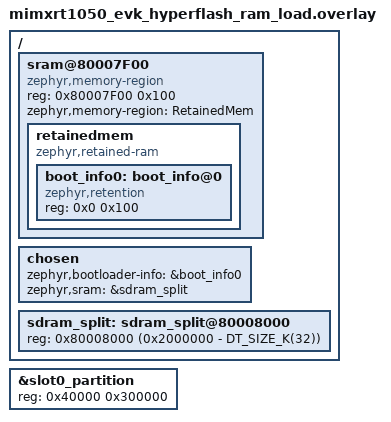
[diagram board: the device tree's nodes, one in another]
/*
 * Copyright (c) 2025 Tenstorrent AI ULC
 *
 * SPDX-License-Identifier: Apache-2.0
 */

/*
 * Layout must match the hyperflash_ram_load overlay file within mcuboot
 * application configuration directory
 */

/delete-node/ &sdram0;

/ {
	sram@80007F00 {
		compatible = "zephyr,memory-region", "mmio-sram";
		reg = <0x80007F00 0x100>;
		zephyr,memory-region = "RetainedMem";
		status = "okay";

		retainedmem {
			compatible = "zephyr,retained-ram";
			status = "okay";
			#address-cells = <1>;
			#size-cells = <1>;

			boot_info0: boot_info@0 {
				compatible = "zephyr,retention";
				status = "okay";
				reg = <0x0 0x100>;
			};
		};
	};

	chosen {
		zephyr,bootloader-info = &boot_info0;
		zephyr,sram = &sdram_split;
	};

	/*
	 * Adjust sdram0 to reserve first 30KB for MCUBoot, and
	 * remaining 2KB for retained memory
	 */
	sdram_split: sdram_split@80008000 {
		reg = <0x80008000 (0x2000000 - DT_SIZE_K(32))>;
	};
};

/* Reduce size of slot 0 to match slot 1 */
&slot0_partition {
	reg = <0x40000 0x300000>;
};
